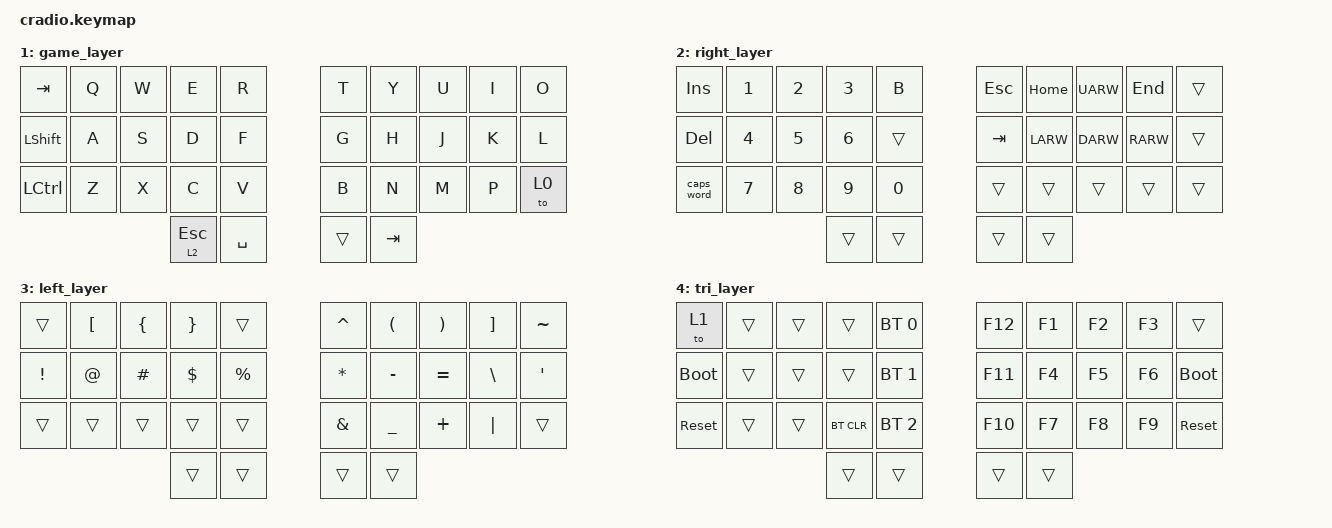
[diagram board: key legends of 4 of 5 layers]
// Copyright (c) 2022 The ZMK Contributors
// SPDX-License-Identifier: MIT

#include <behaviors.dtsi>
#include <dt-bindings/zmk/keys.h>
#include <dt-bindings/zmk/bt.h>

// Home row mods macro
#define HRML(k1,k2,k3,k4) &ht LSHFT k1  &ht LALT k2  &ht LCTRL k3  &ht LGUI k4
#define HRMR(k1,k2,k3,k4) &ht RGUI k1  &ht RCTRL k2  &ht RALT k3  &ht RSHFT k4

/ {
    behaviors {
        ht: hold_tap {
            compatible = "zmk,behavior-hold-tap";
            #binding-cells = <2>;
            flavor = "tap-preferred";
            tapping-term-ms = <220>;
            quick-tap-ms = <150>;
            require-prior-idle-ms = <100>;
            bindings = <&kp>, <&kp>;
        };
    };

    conditional_layers {
        compatible = "zmk,conditional-layers";
        tri_layer {
            if-layers = <2 3>;
            then-layer = <4>;
        };
    };

    keymap {
        compatible = "zmk,keymap";
        default_layer {
            bindings = <
        //╭──────────┬──────────┬──────────┬──────────┬──────────╮   ╭──────────┬──────────┬──────────┬──────────┬──────────╮
        //│  Q       │  W       │  F       │  P       │  B       │   │  J       │  L       │  U       │  Y       │  ; :     │
            &kp Q      &kp W      &kp F      &kp P      &kp B          &kp J      &kp L      &kp U      &kp Y      &kp SEMI
        //├──────────┼──────────┼──────────┼──────────┼──────────┤   ├──────────┼──────────┼──────────┼──────────┼──────────┤
        //│  A       │  R       │  S       │  T       │  G       │   │  K       │  N       │  E       │  I       │  O       │
            HRML(A,        R,         S,         T)     &kp G          &kp K      HRMR(N,        E,         I,        O)
        //├──────────┼──────────┼──────────┼──────────┼──────────┤   ├──────────┼──────────┼──────────┼──────────┼──────────┤
        //│  Z       │  X       │  C       │  D       │  V       │   │  M       │  H       │ , <      │ . >      │ / ?      │
            &kp Z      &kp X      &kp C      &kp D      &kp V          &kp M      &kp H      &kp COMMA  &kp DOT    &kp FSLH
        //╰──────────┴──────────┴──────────┼──────────┼──────────┤   ├──────────┼──────────┼──────────┴──────────┴──────────╯
                                            &kp BSPC   &lt 3 SPACE     &kp ENTER  &lt 2 TAB
        //                                 ╰──────────┴──────────╯   ╰──────────┴──────────╯
            >;
        };
        game_layer {
            bindings = <
        //╭──────────┬──────────┬──────────┬──────────┬──────────╮   ╭──────────┬──────────┬──────────┬──────────┬──────────╮
        //│          │          │          │          │          │   │          │          │          │          │          │
           &kp TAB     &kp Q     &kp W       &kp E      &kp R          &kp T        &kp Y     &kp U      &kp I      &kp O
        //├──────────┼──────────┼──────────┼──────────┼──────────┤   ├──────────┼──────────┼──────────┼──────────┼──────────┤
        //│          │          │          │          │          │   │          │          │          │          │          │
            &kp LSHFT  &kp A      &kp S      &kp D       &kp F         &kp G      &kp H      &kp J      &kp K      &kp L
        //├──────────┼──────────┼──────────┼──────────┼──────────┤   ├──────────┼──────────┼──────────┼──────────┼──────────┤
        //│          │          │          │          │          │   │          │          │          │          │          │
            &kp LCTRL   &kp Z     &kp X      &kp C      &kp V           &kp B     &kp N     &kp M        &kp P     &to 0    
        //╰──────────┴──────────┴──────────┼──────────┼──────────┤   ├──────────┼──────────┼──────────┴──────────┴──────────╯
                                            &lt 2 ESC   &kp SPACE       &trans     &kp TAB
        //                                 ╰──────────┴──────────╯   ╰──────────┴──────────╯
            >;
        };
        right_layer {
            bindings = <
        //╭──────────┬──────────┬──────────┬──────────┬──────────╮   ╭──────────┬──────────┬──────────┬──────────┬──────────╮
        //│ INSERT   │  1       │  2       │  3       │          │   │   ESC    │ HOME     │ UP       │ END      │          │
            &kp INS    &kp N1     &kp N2     &kp N3     &kp B         &kp ESC     &kp HOME   &kp UARW   &kp END    &trans
        //├──────────┼──────────┼──────────┼──────────┼──────────┤   ├──────────┼──────────┼──────────┼──────────┼──────────┤
        //│ DELETE   │  4       │  5       │  6       │          │   │          │ LEFT     │ DOWN     │ RIGHT    │          │
            &kp DEL    &kp N4     &kp N5     &kp N6     &trans         &kp TAB    &kp LARW   &kp DARW   &kp RARW   &trans
        //├──────────┼──────────┼──────────┼──────────┼──────────┤   ├──────────┼──────────┼──────────┼──────────┼──────────┤
        //│ CAPS     │  7       │  8       │  9       │  0       │   │          │          │          │          │          │
           &caps_word  &kp N7     &kp N8     &kp N9     &kp N0         &trans     &trans     &trans     &trans     &trans
        //╰──────────┴──────────┴──────────┼──────────┼──────────┤   ├──────────┼──────────┼──────────┴──────────┴──────────╯
                                             &trans     &trans         &trans     &trans
        //                                 ╰──────────┴──────────╯   ╰──────────┴──────────╯
            >;
        };

        left_layer {
            bindings = <
        //╭──────────┬──────────┬──────────┬──────────┬──────────╮   ╭──────────┬──────────┬──────────┬──────────┬──────────╮
        //│          │  [       │  {       │  }       │          │   │  ^       │  (       │  )       │  ]       │  ~       │
            &trans     &kp LBKT   &kp LBRC   &kp RBRC   &trans         &kp CARET  &kp LPAR   &kp RPAR   &kp RBKT   &kp TILDE
        //├──────────┼──────────┼──────────┼──────────┼──────────┤   ├──────────┼──────────┼──────────┼──────────┼──────────┤
        //│  !       │  @       │  #       │  $       │  %       │   │  *       │  -       │  =       │  \       │  `       │
            &kp EXCL   &kp AT     &kp HASH   &kp DLLR   &kp PRCNT      &kp ASTRK  &kp MINUS  &kp EQUAL  &kp BSLH   &kp SQT
        //├──────────┼──────────┼──────────┼──────────┼──────────┤   ├──────────┼──────────┼──────────┼──────────┼──────────┤
        //│          │          │          │          │          │   │  &       │  _       │  +       │  │       │          │
            &trans     &trans     &trans     &trans     &trans         &kp AMPS   &kp UNDER  &kp PLUS   &kp PIPE   &trans
        //╰──────────┴──────────┴──────────┼──────────┼──────────┤   ├──────────┼──────────┼──────────┴──────────┴──────────╯
                                             &trans     &trans         &trans     &trans
        //                                 ╰──────────┴──────────╯   ╰──────────┴──────────╯
            >;
        };

        tri_layer {
            bindings = <
        //╭──────────┬──────────┬──────────┬──────────┬──────────╮   ╭──────────┬──────────┬──────────┬──────────┬──────────╮
        //│  GAME    │          │          │          │PROFILE 0 │   │          │          │          │          │          │
            &to 1      &trans     &trans     &trans  &bt BT_SEL 0     &kp F12     &kp F1     &kp F2     &kp F3    &trans
        //├──────────┼──────────┼──────────┼──────────┼──────────┤   ├──────────┼──────────┼──────────┼──────────┼──────────┤
        //│BOOTLOADER│          │          │          │PROFILE 1 │   │          │          │          │          │BOOTLOADER│
          &bootloader  &trans     &trans     &trans    &bt BT_SEL 1    &kp F11    &kp F4     &kp F5     &kp F6    &bootloader
        //├──────────┼──────────┼──────────┼──────────┼──────────┤   ├──────────┼──────────┼──────────┼──────────┼──────────┤
        //│  RESET   │          │          │ CLEAR BT │PROFILE 2 │   │          │          │          │          │  RESET   │
           &sys_reset  &trans     &trans   &bt BT_CLR &bt BT_SEL 2     &kp F10     &kp F7     &kp F8     &kp F9    &sys_reset
        //╰──────────┴──────────┴──────────┼──────────┼──────────┤   ├──────────┼──────────┼──────────┴──────────┴──────────╯
                                             &trans     &trans         &trans     &trans
        //                                 ╰──────────┴──────────╯   ╰──────────┴──────────╯
            >;
        };
    };
};
